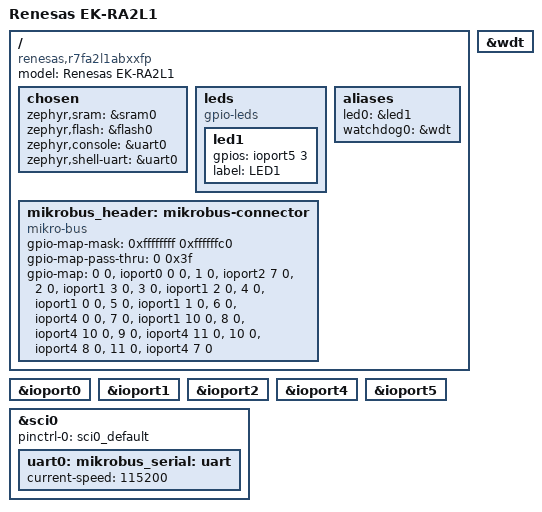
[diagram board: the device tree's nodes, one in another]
/**
 * Copyright (c) 2021-2024 MUNIC SA
 * Copyright (c) 2024 Renesas Electronics Corporation
 *
 * DTS for Renesas EK-RA2L1 eval. board
 *
 * SPDX-License-Identifier: Apache-2.0
 */

/dts-v1/;

#include <renesas/ra/ra2/ra2l1.dtsi>
#include <renesas/ra/ra2/r7fa2l1xb.dtsi>
#include <renesas/ra/ra2/r7fa2l1xxxxfp.dtsi>

#include <zephyr/dt-bindings/gpio/gpio.h>
#include "ek_ra2l1-pinctrl.dtsi"

/ {
	model = "Renesas EK-RA2L1";
	compatible = "renesas,r7fa2l1abxxfp", "renesas,ra2l1";

	chosen {
		zephyr,sram = &sram0;
		zephyr,flash = &flash0;
		zephyr,console = &uart0;
		zephyr,shell-uart = &uart0;
	};

	leds {
		compatible = "gpio-leds";

		led1: led1 {
			gpios = <&ioport5 3 GPIO_ACTIVE_HIGH>;
			label = "LED1";
		};
	};

	mikrobus_header: mikrobus-connector {
		compatible = "mikro-bus";
		#gpio-cells = <2>;
		gpio-map-mask = <0xffffffff 0xffffffc0>;
		gpio-map-pass-thru = <0 0x3f>;
		gpio-map =	<0 0 &ioport0 0 0>,	/* AN  */
				<1 0 &ioport2 7 0>,	/* RST */
				<2 0 &ioport1 3 0>,	/* CS   */
				<3 0 &ioport1 2 0>,	/* SCK  */
				<4 0 &ioport1 0 0>,	/* MISO */
				<5 0 &ioport1 1 0>,	/* MOSI */
							/* +3.3V */
							/* GND */
				<6 0 &ioport4 0 0>,	/* PWM  */
				<7 0 &ioport1 10 0>,	/* INT  */
				<8 0 &ioport4 10 0>,	/* RX   */
				<9 0 &ioport4 11 0>,	/* TX   */
				<10 0 &ioport4 8 0>,	/* SCL  */
				<11 0 &ioport4 7 0>;	/* SDA  */
							/* +5V */
							/* GND */
	};

	aliases {
		led0 = &led1;
		watchdog0 = &wdt;
	};
};

&ioport0 {
	status = "okay";
};

&ioport1 {
	status = "okay";
};

&ioport2 {
	status = "okay";
};

&ioport4 {
	status = "okay";
};

&ioport5 {
	status = "okay";
};

&sci0 {
	pinctrl-0 = <&sci0_default>;
	pinctrl-names = "default";
	status = "okay";

	uart0: uart {
		current-speed = <115200>;
		status = "okay";
	};
};

&wdt {
	status = "okay";
};

mikrobus_serial: &uart0 {};
